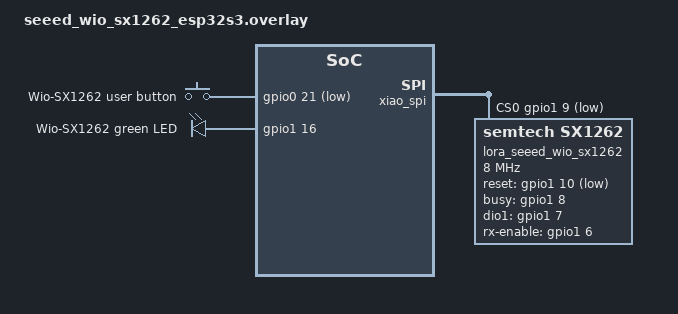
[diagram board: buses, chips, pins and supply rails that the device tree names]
/*
 * Copyright (c) 2026 Marcin Niestroj
 *
 * SPDX-License-Identifier: Apache-2.0
 */

#include <freq.h>
#include <zephyr/dt-bindings/gpio/gpio.h>
#include <zephyr/dt-bindings/input/input-event-codes.h>
#include <zephyr/dt-bindings/lora/sx126x.h>

/ {
	buttons {
		compatible = "gpio-keys";

		button_seeed_wio_sx1262: button_0 {
			gpios = <&gpio0 21 (GPIO_PULL_UP | GPIO_ACTIVE_LOW)>;
			label = "Wio-SX1262 user button";
			zephyr,code = <INPUT_KEY_0>;
		};
	};

	aliases {
		lora0 = &lora_seeed_wio_sx1262;
		sw0 = &button_seeed_wio_sx1262;
	};
};

&led0 {
	gpios = <&gpio1 16 GPIO_ACTIVE_HIGH>;
	label = "Wio-SX1262 green LED";
};

&xiao_spi {
	status = "okay";
	cs-gpios = <&gpio1 9 GPIO_ACTIVE_LOW>;

	lora_seeed_wio_sx1262: lora@0 {
		compatible = "semtech,sx1262";
		reg = <0>;
		spi-max-frequency = <DT_FREQ_M(8)>;
		reset-gpios = <&gpio1 10 (GPIO_ACTIVE_LOW | GPIO_OPEN_DRAIN)>;
		busy-gpios = <&gpio1 8 GPIO_ACTIVE_HIGH>;
		dio1-gpios = <&gpio1 7 GPIO_ACTIVE_HIGH>;
		rx-enable-gpios = <&gpio1 6 GPIO_ACTIVE_HIGH>;
		dio2-tx-enable;
		dio3-tcxo-voltage = <SX126X_DIO3_TCXO_1V8>;
		tcxo-power-startup-delay-ms = <5>;
	};
};
